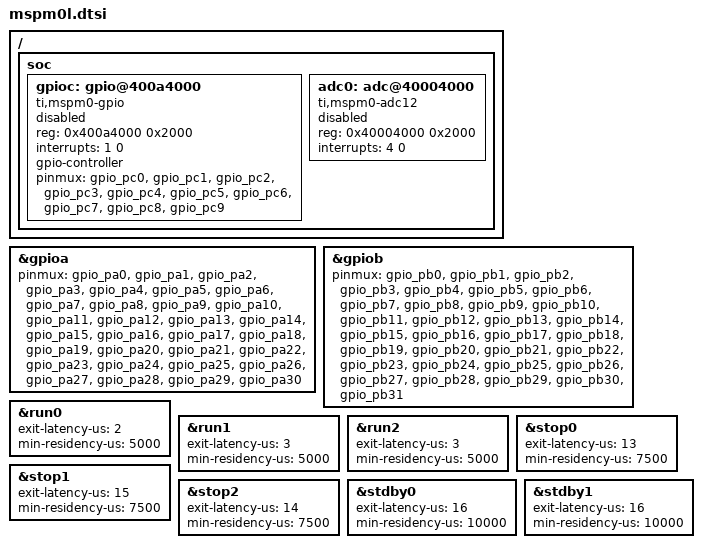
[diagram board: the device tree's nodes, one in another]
/*
 * Copyright (c) 2025 Texas Instruments
 * Copyright (c) 2025 Linumiz GmbH
 *
 * SPDX-License-Identifier: Apache-2.0
 */

#include <ti/mspm0/mspm0.dtsi>
#include <dt-bindings/pinctrl/mspm0-pinctrl.h>

&gpioa {
	pinmux = <&gpio_pa0>,
		 <&gpio_pa1>,
		 <&gpio_pa2>,
		 <&gpio_pa3>,
		 <&gpio_pa4>,
		 <&gpio_pa5>,
		 <&gpio_pa6>,
		 <&gpio_pa7>,
		 <&gpio_pa8>,
		 <&gpio_pa9>,
		 <&gpio_pa10>,
		 <&gpio_pa11>,
		 <&gpio_pa12>,
		 <&gpio_pa13>,
		 <&gpio_pa14>,
		 <&gpio_pa15>,
		 <&gpio_pa16>,
		 <&gpio_pa17>,
		 <&gpio_pa18>,
		 <&gpio_pa19>,
		 <&gpio_pa20>,
		 <&gpio_pa21>,
		 <&gpio_pa22>,
		 <&gpio_pa23>,
		 <&gpio_pa24>,
		 <&gpio_pa25>,
		 <&gpio_pa26>,
		 <&gpio_pa27>,
		 <&gpio_pa28>,
		 <&gpio_pa29>,
		 <&gpio_pa30>;
};

&gpiob {
	pinmux = <&gpio_pb0>,
		 <&gpio_pb1>,
		 <&gpio_pb2>,
		 <&gpio_pb3>,
		 <&gpio_pb4>,
		 <&gpio_pb5>,
		 <&gpio_pb6>,
		 <&gpio_pb7>,
		 <&gpio_pb8>,
		 <&gpio_pb9>,
		 <&gpio_pb10>,
		 <&gpio_pb11>,
		 <&gpio_pb12>,
		 <&gpio_pb13>,
		 <&gpio_pb14>,
		 <&gpio_pb15>,
		 <&gpio_pb16>,
		 <&gpio_pb17>,
		 <&gpio_pb18>,
		 <&gpio_pb19>,
		 <&gpio_pb20>,
		 <&gpio_pb21>,
		 <&gpio_pb22>,
		 <&gpio_pb23>,
		 <&gpio_pb24>,
		 <&gpio_pb25>,
		 <&gpio_pb26>,
		 <&gpio_pb27>,
		 <&gpio_pb28>,
		 <&gpio_pb29>,
		 <&gpio_pb30>,
		 <&gpio_pb31>;
};

/ {
	soc {
		gpioc: gpio@400a4000 {
			compatible = "ti,mspm0-gpio";
			reg = <0x400a4000 0x2000>;
			interrupts = <1 0>;
			status = "disabled";
			gpio-controller;
			#gpio-cells = <2>;
			pinmux = <&gpio_pc0>,
				 <&gpio_pc1>,
				 <&gpio_pc2>,
				 <&gpio_pc3>,
				 <&gpio_pc4>,
				 <&gpio_pc5>,
				 <&gpio_pc6>,
				 <&gpio_pc7>,
				 <&gpio_pc8>,
				 <&gpio_pc9>;
		};

		adc0: adc@40004000 {
			compatible = "ti,mspm0-adc12";
			reg = <0x40004000 0x2000>;
			interrupts = <4 0>;
			status = "disabled";
			#io-channel-cells = <1>;
		};
	};
};

&run0 {
	exit-latency-us = <2>; /* 1.5us */
	min-residency-us = <5000>;
};

&run1 {
	exit-latency-us = <3>; /* 2.1us */
	min-residency-us = <5000>;
};

&run2 {
	exit-latency-us = <3>; /* 2.5us */
	min-residency-us = <5000>;
};

&stop0 {
	exit-latency-us = <13>; /* 12.5us */
	min-residency-us = <7500>;
};

&stop1 {
	exit-latency-us = <15>; /* 14.6us */
	min-residency-us = <7500>;
};

&stop2 {
	exit-latency-us = <14>; /* 13.5us */
	min-residency-us = <7500>;
};

&stdby0 {
	exit-latency-us = <16>; /* 15.7us */
	min-residency-us = <10000>;
};

&stdby1 {
	exit-latency-us = <16>; /* 15.7us */
	min-residency-us = <10000>;
};
